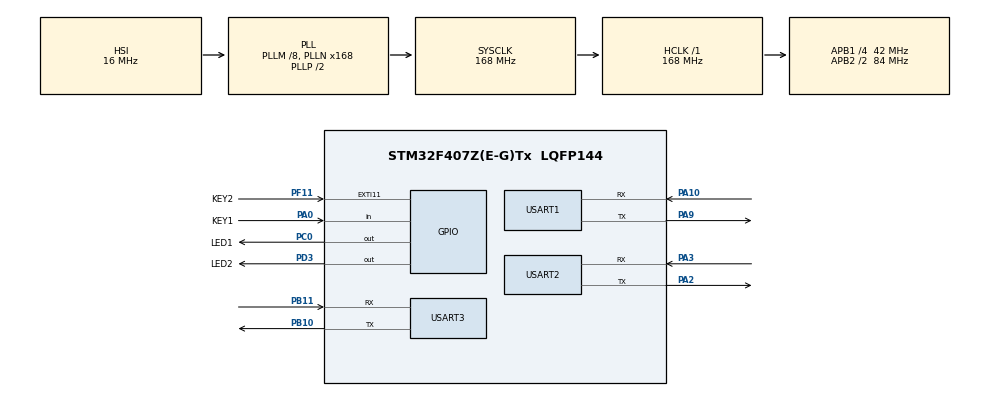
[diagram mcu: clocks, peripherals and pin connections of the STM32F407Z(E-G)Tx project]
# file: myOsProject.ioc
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Mcu.Family=STM32F4
Mcu.Name=STM32F407Z(E-G)Tx
Mcu.Package=LQFP144
NVIC.EXTI15_10_IRQn=true\:0\:0\:false\:false\:true\:true\:true
NVIC.PriorityGroup=NVIC_PRIORITYGROUP_4
NVIC.TIM1_UP_TIM10_IRQn=true\:0\:0\:false\:false\:true\:false\:true
NVIC.TimeBase=TIM1_UP_TIM10_IRQn
NVIC.TimeBaseIP=TIM1
NVIC.USART1_IRQn=true\:0\:0\:false\:false\:true\:true\:true
NVIC.USART2_IRQn=true\:0\:0\:false\:false\:true\:true\:true
NVIC.USART3_IRQn=true\:0\:0\:false\:false\:true\:true\:true
PA0-WKUP.GPIO_Label=KEY1
PA0-WKUP.GPIO_PuPd=GPIO_PULLDOWN
PA0-WKUP.Signal=GPIO_Input
PA10.Mode=Asynchronous
PA10.Signal=USART1_RX
PA13.Mode=Serial_Wire
PA13.Signal=SYS_JTMS-SWDIO
PA14.Mode=Serial_Wire
PA14.Signal=SYS_JTCK-SWCLK
PA2.Mode=Asynchronous
PA2.Signal=USART2_TX
PA3.Mode=Asynchronous
PA3.Signal=USART2_RX
PA9.Mode=Asynchronous
PA9.Signal=USART1_TX
PB10.Mode=Asynchronous
PB10.Signal=USART3_TX
PB11.Mode=Asynchronous
PB11.Signal=USART3_RX
PC0.GPIO_Label=LED1
PC0.PinState=GPIO_PIN_SET
PC0.Signal=GPIO_Output
PD3.GPIO_Label=LED2
PD3.PinState=GPIO_PIN_SET
PD3.Signal=GPIO_Output
PF11.GPIO_Label=KEY2
PF11.GPIO_PuPd=GPIO_PULLDOWN
PF11.Signal=GPXTI11
PH0-OSC_IN.Mode=HSE-External-Oscillator
PH0-OSC_IN.Signal=RCC_OSC_IN
PH1-OSC_OUT.Mode=HSE-External-Oscillator
PH1-OSC_OUT.Signal=RCC_OSC_OUT
ProjectManager.HeapSize=0x200
ProjectManager.StackSize=0x400
ProjectManager.TargetToolchain=STM32CubeIDE
RCC.48MHZClocksFreq_Value=84000000
RCC.AHBFreq_Value=168000000
RCC.APB1CLKDivider=RCC_HCLK_DIV4
RCC.APB1Freq_Value=42000000
RCC.APB1TimFreq_Value=84000000
RCC.APB2CLKDivider=RCC_HCLK_DIV2
RCC.APB2Freq_Value=84000000
RCC.APB2TimFreq_Value=168000000
RCC.CortexFreq_Value=168000000
RCC.HCLKFreq_Value=168000000
RCC.HSE_VALUE=25000000
RCC.HSI_VALUE=16000000
RCC.LSE_VALUE=32768
RCC.PLLM=8
RCC.PLLN=168
RCC.SYSCLKFreq_VALUE=168000000
RCC.SYSCLKSource=RCC_SYSCLKSOURCE_PLLCLK
RCC.VCOOutputFreq_Value=336000000
USART1.VirtualMode=VM_ASYNC
USART2.VirtualMode=VM_ASYNC
USART3.VirtualMode=VM_ASYNC
VP_SYS_VS_tim1.Mode=TIM1
board=custom

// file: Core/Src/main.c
/* USER CODE BEGIN Header */
/**
  ******************************************************************************
  * @file           : main.c
  * @brief          : Main program body
  ******************************************************************************
  * @attention
  *
  * <h2><center>&copy; Copyright (c) 2020 STMicroelectronics.
  * All rights reserved.</center></h2>
  *
  * This software component is licensed by ST under BSD 3-Clause license,
  * the "License"; You may not use this file except in compliance with the
  * License. You may obtain a copy of the License at:
  *                        opensource.org/licenses/BSD-3-Clause
  *
  ******************************************************************************
  */
/* USER CODE END Header */
#include "main.h"
#include "usart.h"
#include "gpio.h"

/* USER CODE BEGIN Includes */
#include "cmsis_os.h"
#include "applicationEntry.h"
/* USER CODE END Includes */

void SystemClock_Config(void);

int main(void)
{

  /* MCU Configuration--------------------------------------------------------*/

  /* Reset of all peripherals, Initializes the Flash interface and the Systick. */
  HAL_Init();

  /* Configure the system clock */
  SystemClock_Config();

  /* Initialize all configured peripherals */
  MX_GPIO_Init();
  MX_USART2_UART_Init();
  MX_USART1_UART_Init();
  MX_USART3_UART_Init();
  /* USER CODE BEGIN 2 */
	osKernelInitialize(); //TOS Tiny kernel initialize
	applicationEntry();
	osKernelStart(); //Start TOS Tiny
  /* USER CODE END 2 */

  /* Infinite loop */
  while (1)
  {

    /* USER CODE BEGIN 3 */
//		HAL_Delay(1000);
//		HAL_GPIO_TogglePin(LED1_GPIO_Port,LED1_Pin);
  }
  /* USER CODE END 3 */
}

void SystemClock_Config(void)
{
  RCC_OscInitTypeDef RCC_OscInitStruct = {0};
  RCC_ClkInitTypeDef RCC_ClkInitStruct = {0};

  /** Configure the main internal regulator output voltage
  */
  __HAL_RCC_PWR_CLK_ENABLE();
  __HAL_PWR_VOLTAGESCALING_CONFIG(PWR_REGULATOR_VOLTAGE_SCALE1);
  /** Initializes the RCC Oscillators according to the specified parameters
  * in the RCC_OscInitTypeDef structure.
  */
  RCC_OscInitStruct.OscillatorType = RCC_OSCILLATORTYPE_HSI;
  RCC_OscInitStruct.HSIState = RCC_HSI_ON;
  RCC_OscInitStruct.HSICalibrationValue = RCC_HSICALIBRATION_DEFAULT;
  RCC_OscInitStruct.PLL.PLLState = RCC_PLL_ON;
  RCC_OscInitStruct.PLL.PLLSource = RCC_PLLSOURCE_HSI;
  RCC_OscInitStruct.PLL.PLLM = 8;
  RCC_OscInitStruct.PLL.PLLN = 168;
  RCC_OscInitStruct.PLL.PLLP = RCC_PLLP_DIV2;
  RCC_OscInitStruct.PLL.PLLQ = 4;
  if (HAL_RCC_OscConfig(&RCC_OscInitStruct) != HAL_OK)
  {
    Error_Handler();
  }
  /** Initializes the CPU, AHB and APB buses clocks
  */
  RCC_ClkInitStruct.ClockType = RCC_CLOCKTYPE_HCLK|RCC_CLOCKTYPE_SYSCLK
                              |RCC_CLOCKTYPE_PCLK1|RCC_CLOCKTYPE_PCLK2;
  RCC_ClkInitStruct.SYSCLKSource = RCC_SYSCLKSOURCE_PLLCLK;
  RCC_ClkInitStruct.AHBCLKDivider = RCC_SYSCLK_DIV1;
  RCC_ClkInitStruct.APB1CLKDivider = RCC_HCLK_DIV4;
  RCC_ClkInitStruct.APB2CLKDivider = RCC_HCLK_DIV2;

  if (HAL_RCC_ClockConfig(&RCC_ClkInitStruct, FLASH_LATENCY_5) != HAL_OK)
  {
    Error_Handler();
  }
}

void HAL_TIM_PeriodElapsedCallback(TIM_HandleTypeDef *htim)
{
  if (htim->Instance == TIM1) {
    HAL_IncTick();
  }
}

void Error_Handler(void)
{
}

/************************ (C) COPYRIGHT STMicroelectronics *****END OF FILE****/
